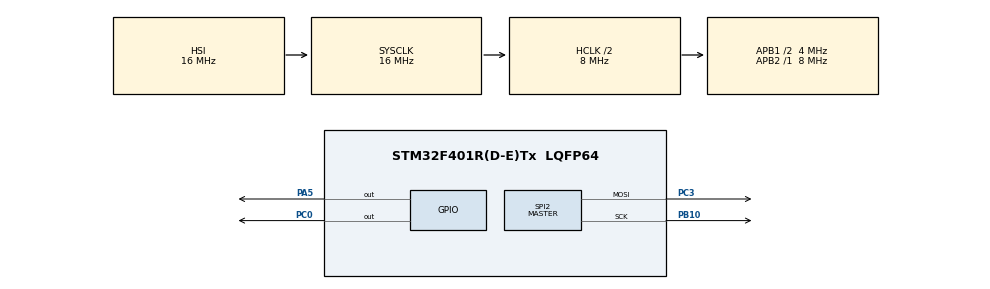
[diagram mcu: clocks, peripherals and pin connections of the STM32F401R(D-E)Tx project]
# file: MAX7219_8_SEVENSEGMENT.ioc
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Mcu.Family=STM32F4
Mcu.Name=STM32F401R(D-E)Tx
Mcu.Package=LQFP64
NVIC.PriorityGroup=NVIC_PRIORITYGROUP_0
PA13.Mode=Serial_Wire
PA13.Signal=SYS_JTMS-SWDIO
PA14.Mode=Serial_Wire
PA14.Signal=SYS_JTCK-SWCLK
PA5.Signal=GPIO_Output
PB10.Mode=TX_Only_Simplex_Unidirect_Master
PB10.Signal=SPI2_SCK
PC0.Signal=GPIO_Output
PC3.Mode=TX_Only_Simplex_Unidirect_Master
PC3.Signal=SPI2_MOSI
PH0\ -\ OSC_IN.Mode=HSE-External-Oscillator
PH0\ -\ OSC_IN.Signal=RCC_OSC_IN
PH1\ -\ OSC_OUT.Mode=HSE-External-Oscillator
PH1\ -\ OSC_OUT.Signal=RCC_OSC_OUT
ProjectManager.HeapSize=0x200
ProjectManager.StackSize=0x400
ProjectManager.TargetToolchain=STM32CubeIDE
RCC.48MHZClocksFreq_Value=18285714.285714287
RCC.AHBCLKDivider=RCC_SYSCLK_DIV2
RCC.AHBFreq_Value=8000000
RCC.APB1CLKDivider=RCC_HCLK_DIV2
RCC.APB1Freq_Value=4000000
RCC.APB1TimFreq_Value=8000000
RCC.APB2Freq_Value=8000000
RCC.APB2TimFreq_Value=8000000
RCC.CortexFreq_Value=8000000
RCC.HCLKFreq_Value=8000000
RCC.HSE_VALUE=8000000
RCC.HSI_VALUE=16000000
RCC.LSE_VALUE=32768
RCC.PLLM=8
RCC.PLLN=64
RCC.PLLQ=7
RCC.SYSCLKFreq_VALUE=16000000
RCC.VCOOutputFreq_Value=128000000
SPI2.BaudRatePrescaler=SPI_BAUDRATEPRESCALER_8
SPI2.DataSize=SPI_DATASIZE_8BIT
SPI2.Direction=SPI_DIRECTION_2LINES
SPI2.Mode=SPI_MODE_MASTER
SPI2.VirtualType=VM_MASTER
TIM10.Prescaler=8000-1
VP_TIM10_VS_ClockSourceINT.Mode=Enable_Timer
board=NUCLEO-F401RE

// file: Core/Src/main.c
/* USER CODE BEGIN Header */
/**
  ******************************************************************************
  * @file           : main.c
  * @brief          : Main program body
  ******************************************************************************
  * @attention
  *
  * Copyright (c) 2023 STMicroelectronics.
  * All rights reserved.
  *
  * This software is licensed under terms that can be found in the LICENSE file
  * in the root directory of this software component.
  * If no LICENSE file comes with this software, it is provided AS-IS.
  *
  ******************************************************************************
  */
/* USER CODE END Header */
#include "main.h"

/* USER CODE BEGIN Includes */
#include "MAX7219.h"
/* USER CODE END Includes */

SPI_HandleTypeDef hspi2;

TIM_HandleTypeDef htim10;

void SystemClock_Config(void);
static void MX_GPIO_Init(void);
static void MX_SPI2_Init(void);
static void MX_TIM10_Init(void);

/* USER CODE BEGIN 0 */
/*
 * @DecodeRange
 * Note: DecodeRange value determines digits acording Code B
 */

/*
 * @ScanMode
 * Note: The scan-limit register sets how many digits are displayed,
from 1 to 8.
 */

/*
 * @IntensityValue
 * Note: Display brightness can be controlled
 */
uint8_t DecodeRange = Decode_7;
uint8_t ScanMode = ScanEight;
uint8_t IntensityValue = Intensity_1;

void Delay(uint16_t Delay){
	__HAL_TIM_SET_COUNTER(&htim10,0);
	while(__HAL_TIM_GET_COUNTER(&htim10)<Delay);
}
/* USER CODE END 0 */

int main(void)
{

  /* MCU Configuration--------------------------------------------------------*/

  /* Reset of all peripherals, Initializes the Flash interface and the Systick. */
  HAL_Init();

  /* Configure the system clock */
  SystemClock_Config();

  /* Initialize all configured peripherals */
  MX_GPIO_Init();
  MX_SPI2_Init();
  MX_TIM10_Init();
  HAL_TIM_Base_Start(&htim10);
  /* USER CODE BEGIN 2 */
  Max7219_Init(DecodeRange, ScanMode, IntensityValue);
  /* USER CODE END 2 */

  /* Infinite loop */
  while (1)
  {

    /* USER CODE BEGIN 3 */
	  /*
	  	  PrintDigit(8, H_letter,DotEn);
	 	  PrintDigit(7, E_letter,DotEn);
	 	  PrintDigit(6, L_letter,DotEn);
	 	  PrintDigit(5, P_letter,DotEn);
	 	  HAL_Delay(500);

	 	  CleanDigits(DecodeRange);

	 	  PrintDigit(4, H_letter,DotDis);
	 	  PrintDigit(3, E_letter,DotDis);
	 	  PrintDigit(2, L_letter,DotDis);
	 	  PrintDigit(1, P_letter,DotDis);
	 	  HAL_Delay(500);
	   */

		  PrintNumber(12345678,DotDis);
		  HAL_Delay(1000);

	 	  //CleanDigits(DecodeRange);

  }
  /* USER CODE END 3 */
}

void SystemClock_Config(void)
{
  RCC_OscInitTypeDef RCC_OscInitStruct = {0};
  RCC_ClkInitTypeDef RCC_ClkInitStruct = {0};

  /** Configure the main internal regulator output voltage
  */
  __HAL_RCC_PWR_CLK_ENABLE();
  __HAL_PWR_VOLTAGESCALING_CONFIG(PWR_REGULATOR_VOLTAGE_SCALE2);

  /** Initializes the RCC Oscillators according to the specified parameters
  * in the RCC_OscInitTypeDef structure.
  */
  RCC_OscInitStruct.OscillatorType = RCC_OSCILLATORTYPE_HSI;
  RCC_OscInitStruct.HSIState = RCC_HSI_ON;
  RCC_OscInitStruct.HSICalibrationValue = RCC_HSICALIBRATION_DEFAULT;
  RCC_OscInitStruct.PLL.PLLState = RCC_PLL_NONE;
  if (HAL_RCC_OscConfig(&RCC_OscInitStruct) != HAL_OK)
  {
    Error_Handler();
  }

  /** Initializes the CPU, AHB and APB buses clocks
  */
  RCC_ClkInitStruct.ClockType = RCC_CLOCKTYPE_HCLK|RCC_CLOCKTYPE_SYSCLK
                              |RCC_CLOCKTYPE_PCLK1|RCC_CLOCKTYPE_PCLK2;
  RCC_ClkInitStruct.SYSCLKSource = RCC_SYSCLKSOURCE_HSI;
  RCC_ClkInitStruct.AHBCLKDivider = RCC_SYSCLK_DIV2;
  RCC_ClkInitStruct.APB1CLKDivider = RCC_HCLK_DIV2;
  RCC_ClkInitStruct.APB2CLKDivider = RCC_HCLK_DIV1;

  if (HAL_RCC_ClockConfig(&RCC_ClkInitStruct, FLASH_LATENCY_0) != HAL_OK)
  {
    Error_Handler();
  }
}

static void MX_SPI2_Init(void)
{

  /* SPI2 parameter configuration*/
  hspi2.Instance = SPI2;
  hspi2.Init.Mode = SPI_MODE_MASTER;
  hspi2.Init.Direction = SPI_DIRECTION_2LINES;
  hspi2.Init.DataSize = SPI_DATASIZE_8BIT;
  hspi2.Init.CLKPolarity = SPI_POLARITY_LOW;
  hspi2.Init.CLKPhase = SPI_PHASE_1EDGE;
  hspi2.Init.NSS = SPI_NSS_SOFT;
  hspi2.Init.BaudRatePrescaler = SPI_BAUDRATEPRESCALER_8;
  hspi2.Init.FirstBit = SPI_FIRSTBIT_MSB;
  hspi2.Init.TIMode = SPI_TIMODE_DISABLE;
  hspi2.Init.CRCCalculation = SPI_CRCCALCULATION_DISABLE;
  hspi2.Init.CRCPolynomial = 10;
  if (HAL_SPI_Init(&hspi2) != HAL_OK)
  {
    Error_Handler();
  }

}

static void MX_TIM10_Init(void)
{

  htim10.Instance = TIM10;
  htim10.Init.Prescaler = 8000-1;
  htim10.Init.CounterMode = TIM_COUNTERMODE_UP;
  htim10.Init.Period = 65535;
  htim10.Init.ClockDivision = TIM_CLOCKDIVISION_DIV1;
  htim10.Init.AutoReloadPreload = TIM_AUTORELOAD_PRELOAD_DISABLE;
  if (HAL_TIM_Base_Init(&htim10) != HAL_OK)
  {
    Error_Handler();
  }

}

static void MX_GPIO_Init(void)
{
  GPIO_InitTypeDef GPIO_InitStruct = {0};

  /* GPIO Ports Clock Enable */
  __HAL_RCC_GPIOH_CLK_ENABLE();
  __HAL_RCC_GPIOC_CLK_ENABLE();
  __HAL_RCC_GPIOA_CLK_ENABLE();
  __HAL_RCC_GPIOB_CLK_ENABLE();

  /*Configure GPIO pin Output Level */
  HAL_GPIO_WritePin(GPIOC, GPIO_PIN_0, GPIO_PIN_RESET);

  /*Configure GPIO pin Output Level */
  HAL_GPIO_WritePin(GPIOA, GPIO_PIN_5, GPIO_PIN_RESET);

  /*Configure GPIO pin : PC0 */
  GPIO_InitStruct.Pin = GPIO_PIN_0;
  GPIO_InitStruct.Mode = GPIO_MODE_OUTPUT_PP;
  GPIO_InitStruct.Pull = GPIO_NOPULL;
  GPIO_InitStruct.Speed = GPIO_SPEED_FREQ_LOW;
  HAL_GPIO_Init(GPIOC, &GPIO_InitStruct);

  /*Configure GPIO pin : PA5 */
  GPIO_InitStruct.Pin = GPIO_PIN_5;
  GPIO_InitStruct.Mode = GPIO_MODE_OUTPUT_PP;
  GPIO_InitStruct.Pull = GPIO_NOPULL;
  GPIO_InitStruct.Speed = GPIO_SPEED_FREQ_LOW;
  HAL_GPIO_Init(GPIOA, &GPIO_InitStruct);

}

void Error_Handler(void)
{
  __disable_irq();
  while (1)
  {
  }
}
